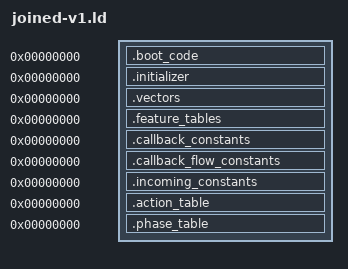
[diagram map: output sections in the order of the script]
OUTPUT_ARCH(riscv)
SECTIONS
{
 .boot_code 0 : SUBALIGN(2) { *(.boot_code)
  *(.text.tsl9_registered_callbacks_provider_9508)
  *(.text.tsl9_record_actions_block_9510)
  *(.text.tsl9_record_actions_block_951a)
  *(.text.tsl9_record_actions_block_9548)
  *(.text.tsl9_record_dispatch_provider_954e)
  *(.text.tsl9_record_actions_block_9556)
  *(.text.tsl9_record_actions_block_9560)
  *(.text.tsl9_record_actions_block_95b6)
  *(.text.tsl9_record_dispatch_provider_95bc)
  *(.text.tsl9_record_actions_block_95c4)
  *(.text.tsl9_record_actions_block_95ce)
  *(.text.tsl9_record_actions_block_9608)
  *(.text.tsl9_record_dispatch_provider_96a2)
  *(.text.tsl9_record_actions_block_96aa)
  *(.text.tsl9_record_actions_block_96b4)
  *(.text.tsl9_record_actions_block_9736)
  *(.text.tsl9_record_dispatch_provider_bd0a)
  *(.text.tsl9_record_actions_block_bd16)
  *(.text.tsl9_record_actions_block_bd1e)
  *(.text.tsl9_record_actions_block_bd24)
  *(.text.tsl9_record_actions_block_bd28)
  *(.text.tsl9_record_actions_block_bd32)
  *(.text.tsl9_record_actions_block_bd38)
  *(.text.tsl9_record_dispatch_provider_bd5a)
  *(.text.tsl9_record_dispatch_provider_bd6e)
  *(.text.tsl9_record_actions_block_bd7e)
  *(.text.tsl9_record_dispatch_provider_cc78)
  *(.text.tsl9_record_dispatch_provider_cc8c)
  *(.text.tsl9_record_actions_block_cca2)
  *(.text.tsl9_record_actions_block_cca6)
  *(.text.tsl9_record_actions_block_ccae)
  *(.text.tsl9_record_actions_block_ccb0)
  *(.text.tsl9_record_actions_block_ccb6)
  *(.text.tsl9_record_dispatch_provider_d3c6)
  *(.text.tsl9_record_actions_block_d3d2)
  *(.text.tsl9_feature_external_f1c2)
  *(.text.tsl9_record_actions_block_f1e4)
  *(.text.tsl9_record_actions_block_f1e8)
  *(.text.tsl9_record_actions_block_f1fc)
  *(.text.tsl9_record_actions_block_f206)
  *(.text.tsl9_record_actions_block_f214)
  *(.text.tsl9_record_actions_block_f21e)
  *(.text.tsl9_record_actions_block_f222)
  *(.text.tsl9_record_actions_block_f238)
  *(.text.tsl9_record_actions_block_f242)
  *(.text.tsl9_record_actions_block_f248)
  *(.text.tsl9_record_actions_block_f252)
  *(.text.tsl9_record_actions_block_f254)
  *(.text.tsl9_record_actions_block_f264)
  *(.text.tsl9_record_actions_block_f268)
  *(.text.tsl9_record_actions_block_f26e)
  *(.text.tsl9_record_actions_block_f27c)
  *(.text.tsl9_record_actions_block_f286)
  *(.text.tsl9_record_actions_block_f296)
  *(.text.tsl9_record_actions_block_f2a0)
  *(.text.tsl9_record_actions_block_f2b6)
  *(.text.tsl9_record_actions_block_f2c0)
  *(.text.tsl9_record_actions_block_f2d6)
  *(.text.tsl9_record_actions_block_f2e0)
  *(.text.tsl9_record_actions_block_f2fa)
  *(.text.tsl9_record_actions_block_f304)
  *(.text.tsl9_record_actions_block_f31e)
  *(.text.tsl9_record_actions_block_f332)
  *(.text.tsl9_record_actions_block_f336)
  *(.text.tsl9_record_actions_block_f33c)
  *(.text.tsl9_record_actions_block_f356)
  *(.text.tsl9_record_actions_block_f360)
  *(.text.tsl9_record_actions_block_f366)
  *(.text.tsl9_record_actions_block_f36e)
  *(.text.tsl9_record_actions_block_f38e)
  *(.text.tsl9_record_actions_block_f398)
  *(.text.tsl9_record_actions_block_f3a0)
  *(.text.tsl9_record_actions_block_f3a8)
  *(.text.tsl9_record_actions_block_f3b0)
  *(.text.tsl9_record_actions_block_f3d0)
  *(.text.tsl9_record_actions_block_f3e2)
  *(.text.tsl9_record_actions_block_f3ec)
  *(.text.tsl9_record_actions_block_f3f2)
  *(.text.tsl9_record_actions_block_f3fe)
  *(.text.tsl9_record_actions_block_f400)
  *(.text.tsl9_record_actions_block_f402)
  *(.text.tsl9_record_actions_block_f406)
  *(.text.tsl9_record_dispatch_provider_f672)
  *(.text.tsl9_record_dispatch_provider_f688)
  *(.text.tsl9_record_dispatch_provider_f6ba)
  *(.text.tsl9_record_dispatch_provider_f6ec)
  *(.text.tsl9_record_dispatch_provider_f71e)
  *(.text.tsl9_record_dispatch_provider_f750)
  *(.text.tsl9_record_actions_block_f772)
  *(.text.tsl9_record_actions_block_f774)
  *(.text.tsl9_record_actions_block_f782)
  *(.text.tsl9_record_dispatch_provider_f796)
  *(.text.tsl9_record_actions_block_f7b8)
  *(.text.tsl9_record_actions_block_f7ba)
  *(.text.tsl9_record_actions_block_f7c8)
  *(.text.tsl9_record_dispatch_provider_f97c)
  *(.text.tsl9_record_actions_block_f988)
 }
 .initializer 0 : SUBALIGN(4) { *(.initializer) }
 .vectors 0 : SUBALIGN(4) { *(.vectors) }
 .feature_tables 0 : SUBALIGN(4) { *(.feature_tables) }
 .callback_constants 0 : SUBALIGN(4) { *(.callback_constants) }
 .callback_flow_constants 0 : SUBALIGN(4) { *(.callback_flow_constants) }
 .incoming_constants 0 : SUBALIGN(4) { *(.incoming_constants) }
 .action_table 0 : SUBALIGN(4) { *(.action_table) }
 .phase_table 0 : SUBALIGN(4) { *(.phase_table) }
 /DISCARD/ : { *(.comment) *(.riscv.attributes) *(.llvm_addrsig) }
}
